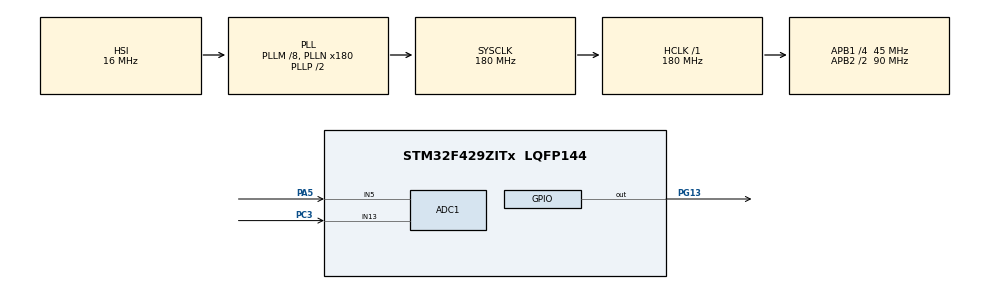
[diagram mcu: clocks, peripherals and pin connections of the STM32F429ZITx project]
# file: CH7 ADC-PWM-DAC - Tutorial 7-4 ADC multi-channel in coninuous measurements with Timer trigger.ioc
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ADC1.Channel-0\#ChannelRegularConversion=ADC_CHANNEL_5
ADC1.Channel-1\#ChannelRegularConversion=ADC_CHANNEL_13
ADC1.ClockPrescaler=ADC_CLOCK_SYNC_PCLK_DIV8
ADC1.ContinuousConvMode=DISABLE
ADC1.EOCSelection=ADC_EOC_SINGLE_CONV
ADC1.ExternalTrigConv=ADC_EXTERNALTRIGCONV_T8_TRGO
ADC1.NbrOfConversion=2
ADC1.NbrOfConversionFlag=1
ADC1.Rank-0\#ChannelRegularConversion=1
ADC1.Rank-1\#ChannelRegularConversion=2
ADC1.SamplingTime-0\#ChannelRegularConversion=ADC_SAMPLETIME_480CYCLES
ADC1.SamplingTime-1\#ChannelRegularConversion=ADC_SAMPLETIME_480CYCLES
ADC1.ScanConvMode=ENABLE
ADC1.master=1
Mcu.Family=STM32F4
Mcu.Name=STM32F429ZITx
Mcu.Package=LQFP144
NVIC.ADC_IRQn=true\:1\:0\:true\:false\:true\:true\:true\:true
NVIC.PriorityGroup=NVIC_PRIORITYGROUP_1
PA5.Signal=ADCx_IN5
PC3.Signal=ADCx_IN13
PG13.Signal=GPIO_Output
ProjectManager.HeapSize=0x200
ProjectManager.StackSize=0x400
ProjectManager.TargetToolchain=STM32CubeIDE
RCC.48MHZClocksFreq_Value=51428571.428571425
RCC.AHBFreq_Value=180000000
RCC.APB1CLKDivider=RCC_HCLK_DIV4
RCC.APB1Freq_Value=45000000
RCC.APB1TimFreq_Value=90000000
RCC.APB2CLKDivider=RCC_HCLK_DIV2
RCC.APB2Freq_Value=90000000
RCC.APB2TimFreq_Value=180000000
RCC.CortexFreq_Value=180000000
RCC.HCLKFreq_Value=180000000
RCC.HSE_VALUE=8000000
RCC.HSI_VALUE=16000000
RCC.LSE_VALUE=32768
RCC.PLLM=8
RCC.PLLN=180
RCC.PLLQ=7
RCC.SYSCLKFreq_VALUE=180000000
RCC.SYSCLKSource=RCC_SYSCLKSOURCE_PLLCLK
RCC.VCOOutputFreq_Value=360000000
SH.ADCx_IN13.0=ADC1_IN13,IN13
SH.ADCx_IN5.0=ADC1_IN5,IN5
TIM8.Period=10000-1
TIM8.Prescaler=18000-1
TIM8.TIM_MasterOutputTrigger=TIM_TRGO_UPDATE
VP_TIM8_VS_ClockSourceINT.Mode=Internal
board=STM32F429I-DISC1

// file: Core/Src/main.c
/* USER CODE BEGIN Header */
/**
  ******************************************************************************
  * @file           : main.c
  * @brief          : Main program body
  ******************************************************************************
  * @attention
  *
  * Copyright (c) 2024 STMicroelectronics.
  * All rights reserved.
  *
  * This software is licensed under terms that can be found in the LICENSE file
  * in the root directory of this software component.
  * If no LICENSE file comes with this software, it is provided AS-IS.
  *
  ******************************************************************************
  */
	/***************************** Tutorial Tags ******************************
	 ADC continuous measurements
	 Hardware trigger Timers
	 **************************************************************************/

	/* 7.4.1 ADC Usage C Language: ******************************************
	* Tutorial 7-4 (modified*): Usage of the ADC module with multiple channels
	* for continuous measurements using Timer trigger the C code
	*

    In this tutorial, form a project with the following specificvation: ADC1 Channels
    5 and 13 of the STM32F4 disco board will be configured to take measurements
    from two potentiometers in scan mode and will be triggered using Timer 8 every
    1 second to take continuous measurements. On the other hand, ADC clock is set to 4.5 MHz
    and sampling time to 480 cycles per sample.

    Finally configure timer to stop after buffer of data is filled and samples to be
    transfered to PC via UART port.

    You can check results of this tutorial in the project sub folder "results"

	PS refer to Fig 7.13 of the book for circuit connections of this tutorial.

	***************************************************************************/
/* USER CODE END Header */
#include "main.h"

/* USER CODE BEGIN Includes */
#include<stdio.h>
#include<math.h>
/* USER CODE END Includes */

/* USER CODE BEGIN PD */
# define Data_stream_size 60
/* USER CODE END PD */

ADC_HandleTypeDef hadc1;

TIM_HandleTypeDef htim8;

/* USER CODE BEGIN PV */
//uint16_t ADC_val[Data_stream_size];
uint16_t ADC_val[Data_stream_size];
float Vref = 2.92, ADC_val_conv_V[Data_stream_size];
uint16_t counter;
/* USER CODE END PV */

void SystemClock_Config(void);
static void MX_GPIO_Init(void);
static void MX_ADC1_Init(void);
static void MX_TIM8_Init(void);

int main(void)
{

  /* MCU Configuration--------------------------------------------------------*/

  /* Reset of all peripherals, Initializes the Flash interface and the Systick. */
  HAL_Init();

  /* Configure the system clock */
  SystemClock_Config();

  /* Initialize all configured peripherals */
  MX_GPIO_Init();
  MX_ADC1_Init();
  MX_TIM8_Init();
  /* USER CODE BEGIN 2 */

  HAL_TIM_Base_Start(&htim8);
  HAL_ADC_Start_IT(&hadc1);

  // CPU is held in sleep mode during ADC conversion.
  //HAL_PWR_EnableSleepOnExit();
  //HAL_PWR_EnterSLEEPMode(PWR_MAINREGULATOR_ON , PWR_SLEEPENTRY_WFI);

  /* USER CODE END 2 */

  /* Infinite loop */
  while (1)
  {

  }
}

void SystemClock_Config(void)
{
  RCC_OscInitTypeDef RCC_OscInitStruct = {0};
  RCC_ClkInitTypeDef RCC_ClkInitStruct = {0};

  /** Configure the main internal regulator output voltage
  */
  __HAL_RCC_PWR_CLK_ENABLE();
  __HAL_PWR_VOLTAGESCALING_CONFIG(PWR_REGULATOR_VOLTAGE_SCALE1);

  /** Initializes the RCC Oscillators according to the specified parameters
  * in the RCC_OscInitTypeDef structure.
  */
  RCC_OscInitStruct.OscillatorType = RCC_OSCILLATORTYPE_HSI;
  RCC_OscInitStruct.HSIState = RCC_HSI_ON;
  RCC_OscInitStruct.HSICalibrationValue = RCC_HSICALIBRATION_DEFAULT;
  RCC_OscInitStruct.PLL.PLLState = RCC_PLL_ON;
  RCC_OscInitStruct.PLL.PLLSource = RCC_PLLSOURCE_HSI;
  RCC_OscInitStruct.PLL.PLLM = 8;
  RCC_OscInitStruct.PLL.PLLN = 180;
  RCC_OscInitStruct.PLL.PLLP = RCC_PLLP_DIV2;
  RCC_OscInitStruct.PLL.PLLQ = 7;
  if (HAL_RCC_OscConfig(&RCC_OscInitStruct) != HAL_OK)
  {
    Error_Handler();
  }

  /** Activate the Over-Drive mode
  */
  if (HAL_PWREx_EnableOverDrive() != HAL_OK)
  {
    Error_Handler();
  }

  /** Initializes the CPU, AHB and APB buses clocks
  */
  RCC_ClkInitStruct.ClockType = RCC_CLOCKTYPE_HCLK|RCC_CLOCKTYPE_SYSCLK
                              |RCC_CLOCKTYPE_PCLK1|RCC_CLOCKTYPE_PCLK2;
  RCC_ClkInitStruct.SYSCLKSource = RCC_SYSCLKSOURCE_PLLCLK;
  RCC_ClkInitStruct.AHBCLKDivider = RCC_SYSCLK_DIV1;
  RCC_ClkInitStruct.APB1CLKDivider = RCC_HCLK_DIV4;
  RCC_ClkInitStruct.APB2CLKDivider = RCC_HCLK_DIV2;

  if (HAL_RCC_ClockConfig(&RCC_ClkInitStruct, FLASH_LATENCY_5) != HAL_OK)
  {
    Error_Handler();
  }
}

static void MX_ADC1_Init(void)
{

  ADC_ChannelConfTypeDef sConfig = {0};

  /** Configure the global features of the ADC (Clock, Resolution, Data Alignment and number of conversion)
  */
  hadc1.Instance = ADC1;
  hadc1.Init.ClockPrescaler = ADC_CLOCK_SYNC_PCLK_DIV8;
  hadc1.Init.Resolution = ADC_RESOLUTION_12B;
  hadc1.Init.ScanConvMode = ENABLE;
  hadc1.Init.ContinuousConvMode = DISABLE;
  hadc1.Init.DiscontinuousConvMode = DISABLE;
  hadc1.Init.ExternalTrigConvEdge = ADC_EXTERNALTRIGCONVEDGE_RISING;
  hadc1.Init.ExternalTrigConv = ADC_EXTERNALTRIGCONV_T8_TRGO;
  hadc1.Init.DataAlign = ADC_DATAALIGN_RIGHT;
  hadc1.Init.NbrOfConversion = 2;
  hadc1.Init.DMAContinuousRequests = DISABLE;
  hadc1.Init.EOCSelection = ADC_EOC_SINGLE_CONV;
  if (HAL_ADC_Init(&hadc1) != HAL_OK)
  {
    Error_Handler();
  }

  /** Configure for the selected ADC regular channel its corresponding rank in the sequencer and its sample time.
  */
  sConfig.Channel = ADC_CHANNEL_5;
  sConfig.Rank = 1;
  sConfig.SamplingTime = ADC_SAMPLETIME_480CYCLES;
  if (HAL_ADC_ConfigChannel(&hadc1, &sConfig) != HAL_OK)
  {
    Error_Handler();
  }

  /** Configure for the selected ADC regular channel its corresponding rank in the sequencer and its sample time.
  */
  sConfig.Channel = ADC_CHANNEL_13;
  sConfig.Rank = 2;
  if (HAL_ADC_ConfigChannel(&hadc1, &sConfig) != HAL_OK)
  {
    Error_Handler();
  }

}

static void MX_TIM8_Init(void)
{

  TIM_ClockConfigTypeDef sClockSourceConfig = {0};
  TIM_MasterConfigTypeDef sMasterConfig = {0};

  htim8.Instance = TIM8;
  htim8.Init.Prescaler = 18000-1;
  htim8.Init.CounterMode = TIM_COUNTERMODE_UP;
  htim8.Init.Period = 10000-1;
  htim8.Init.ClockDivision = TIM_CLOCKDIVISION_DIV1;
  htim8.Init.RepetitionCounter = 0;
  htim8.Init.AutoReloadPreload = TIM_AUTORELOAD_PRELOAD_DISABLE;
  if (HAL_TIM_Base_Init(&htim8) != HAL_OK)
  {
    Error_Handler();
  }
  sClockSourceConfig.ClockSource = TIM_CLOCKSOURCE_INTERNAL;
  if (HAL_TIM_ConfigClockSource(&htim8, &sClockSourceConfig) != HAL_OK)
  {
    Error_Handler();
  }
  sMasterConfig.MasterOutputTrigger = TIM_TRGO_UPDATE;
  sMasterConfig.MasterSlaveMode = TIM_MASTERSLAVEMODE_DISABLE;
  if (HAL_TIMEx_MasterConfigSynchronization(&htim8, &sMasterConfig) != HAL_OK)
  {
    Error_Handler();
  }

}

static void MX_GPIO_Init(void)
{
  GPIO_InitTypeDef GPIO_InitStruct = {0};

  /* GPIO Ports Clock Enable */
  __HAL_RCC_GPIOC_CLK_ENABLE();
  __HAL_RCC_GPIOA_CLK_ENABLE();
  __HAL_RCC_GPIOG_CLK_ENABLE();

  /*Configure GPIO pin Output Level */
  HAL_GPIO_WritePin(GPIOG, GPIO_PIN_13, GPIO_PIN_RESET);

  /*Configure GPIO pin : PG13 */
  GPIO_InitStruct.Pin = GPIO_PIN_13;
  GPIO_InitStruct.Mode = GPIO_MODE_OUTPUT_PP;
  GPIO_InitStruct.Pull = GPIO_NOPULL;
  GPIO_InitStruct.Speed = GPIO_SPEED_FREQ_LOW;
  HAL_GPIO_Init(GPIOG, &GPIO_InitStruct);

}

/* USER CODE BEGIN 4 */
void HAL_ADC_ConvCpltCallback(ADC_HandleTypeDef *hadc)
{
	// Digital value
  HAL_GPIO_TogglePin(GPIOG, GPIO_PIN_13);
  ADC_val[counter] = HAL_ADC_GetValue(&hadc1);
  // Convert the ADC digital value to voltage (in V)
  ADC_val_conv_V[counter] = (Vref/pow(2,12))*ADC_val[counter];

  counter++;

  if (counter == Data_stream_size) HAL_TIM_Base_Stop(&htim8);

  __NOP();

}

/* USER CODE END 4 */

void Error_Handler(void)
{
  __disable_irq();
  while (1)
  {
  }
}
